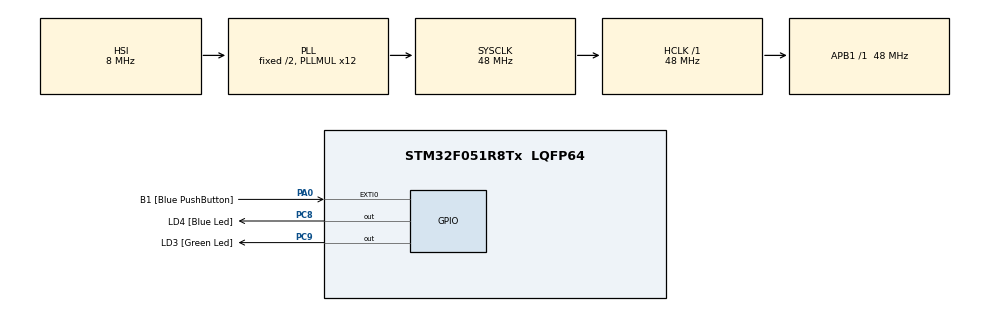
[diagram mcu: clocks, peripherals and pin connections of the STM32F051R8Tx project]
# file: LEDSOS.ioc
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Mcu.Family=STM32F0
Mcu.Name=STM32F051R8Tx
Mcu.Package=LQFP64
PA0.GPIO_Label=B1 [Blue PushButton]
PA0.GPIO_ModeDefaultEXTI=GPIO_MODE_EVT_RISING
PA0.Signal=GPXTI0
PA13.GPIO_Label=SWDIO
PA13.Signal=SYS_SWDIO
PA14.GPIO_Label=SWCLK
PA14.Signal=SYS_SWCLK
PC8.GPIO_Label=LD4 [Blue Led]
PC8.GPIO_PuPd=GPIO_PULLUP
PC8.Signal=GPIO_Output
PC9.GPIO_Label=LD3 [Green Led]
PC9.GPIO_PuPd=GPIO_PULLUP
PC9.Signal=GPIO_Output
ProjectManager.HeapSize=0x200
ProjectManager.StackSize=0x400
ProjectManager.TargetToolchain=TrueSTUDIO
RCC.AHBFreq_Value=48000000
RCC.APB1Freq_Value=48000000
RCC.APB1TimFreq_Value=48000000
RCC.HCLKFreq_Value=48000000
RCC.PLLMUL=RCC_PLL_MUL12
RCC.SYSCLKFreq_VALUE=48000000
RCC.SYSCLKSource=RCC_SYSCLKSOURCE_PLLCLK
board=STM32F0DISCOVERY

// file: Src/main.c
/**
  ******************************************************************************
  * File Name          : main.c
  * Description        : Main program body
  ******************************************************************************
  *
  * COPYRIGHT(c) 2016 STMicroelectronics
  *
  * Redistribution and use in source and binary forms, with or without modification,
  * are permitted provided that the following conditions are met:
  *   1. Redistributions of source code must retain the above copyright notice,
  *      this list of conditions and the following disclaimer.
  *   2. Redistributions in binary form must reproduce the above copyright notice,
  *      this list of conditions and the following disclaimer in the documentation
  *      and/or other materials provided with the distribution.
  *   3. Neither the name of STMicroelectronics nor the names of its contributors
  *      may be used to endorse or promote products derived from this software
  *      without specific prior written permission.
  *
  * THIS SOFTWARE IS PROVIDED BY THE COPYRIGHT HOLDERS AND CONTRIBUTORS "AS IS"
  * AND ANY EXPRESS OR IMPLIED WARRANTIES, INCLUDING, BUT NOT LIMITED TO, THE
  * IMPLIED WARRANTIES OF MERCHANTABILITY AND FITNESS FOR A PARTICULAR PURPOSE ARE
  * DISCLAIMED. IN NO EVENT SHALL THE COPYRIGHT HOLDER OR CONTRIBUTORS BE LIABLE
  * FOR ANY DIRECT, INDIRECT, INCIDENTAL, SPECIAL, EXEMPLARY, OR CONSEQUENTIAL
  * DAMAGES (INCLUDING, BUT NOT LIMITED TO, PROCUREMENT OF SUBSTITUTE GOODS OR
  * SERVICES; LOSS OF USE, DATA, OR PROFITS; OR BUSINESS INTERRUPTION) HOWEVER
  * CAUSED AND ON ANY THEORY OF LIABILITY, WHETHER IN CONTRACT, STRICT LIABILITY,
  * OR TORT (INCLUDING NEGLIGENCE OR OTHERWISE) ARISING IN ANY WAY OUT OF THE USE
  * OF THIS SOFTWARE, EVEN IF ADVISED OF THE POSSIBILITY OF SUCH DAMAGE.
  *
  ******************************************************************************
  */
#include "stm32f0xx_hal.h"

/* USER CODE BEGIN Includes */
#define UNIT 500

/* USER CODE END Includes */

/* USER CODE BEGIN PV */
/* Private variables ---------------------------------------------------------*/

/* USER CODE END PV */

void SystemClock_Config(void);
void Error_Handler(void);
static void MX_GPIO_Init(void);

/* USER CODE BEGIN PFP */
/* Private function prototypes -----------------------------------------------*/

/* USER CODE END PFP */

  void light_On()
  {
	  HAL_GPIO_WritePin(GPIOC, GPIO_PIN_8, GPIO_PIN_SET);
  }

  void light_Off()
  {
	  HAL_GPIO_WritePin(GPIOC, GPIO_PIN_8, GPIO_PIN_RESET);
  }

  void lightOnButtonPressed()
  {
	  uint8_t buttonState;

	  buttonState = HAL_GPIO_ReadPin(GPIOA, GPIO_PIN_0);

	  if (buttonState == 1)
	  	  {
	  		  HAL_GPIO_WritePin(GPIOC, GPIO_PIN_9, GPIO_PIN_SET);
	  	  }
	  else
	  	  {
	  		  HAL_GPIO_WritePin(GPIOC, GPIO_PIN_9, GPIO_PIN_RESET);
	  	  }
  }

  void getStrSize(uint8_t * str)
  {
	  for (int i = 0; i < sizeof(str) - 1; i++)
	  {
		  light_On();
		  HAL_Delay(UNIT);
		  light_Off();
		  HAL_Delay(UNIT);
	  }

	  HAL_Delay(10*UNIT);
  }

  void char_to_morse(uint8_t  symbol)
  {
	  switch (symbol)
	  	  {
	  	      case 'S': light_On(); HAL_Delay(2*UNIT); light_Off(); HAL_Delay(UNIT); return;
	  	      case 'O': light_On(); HAL_Delay(4*UNIT); light_Off(); HAL_Delay(UNIT); return;
	  	      case ' ': light_On(); HAL_Delay(UNIT);  light_Off();  HAL_Delay(UNIT); return;
	  	      default: return;
	  	  }
  }

  void str_to_morse(uint8_t * str)
  {
	  uint8_t symbol;

	  for(int i = 0; i < sizeof(str) - 1; i++)
	  {
	      symbol = str[i];
	      char_to_morse(symbol);
	  }

	  HAL_Delay(10*UNIT);
  }

int main(void)
{

  /* MCU Configuration----------------------------------------------------------*/

  /* Reset of all peripherals, Initializes the Flash interface and the Systick. */
  HAL_Init();

  /* Configure the system clock */
  SystemClock_Config();

  /* Initialize all configured peripherals */
  MX_GPIO_Init();

  /* Infinite loop */
  while (1)
  {

  /* USER CODE BEGIN 3 */

	  //lightOnButtonPressed();

	  //getStrSize("SOS");

	  str_to_morse("SOS");

  }
  /* USER CODE END 3 */

}

/** System Clock Configuration
*/
void SystemClock_Config(void)
{

  RCC_OscInitTypeDef RCC_OscInitStruct;
  RCC_ClkInitTypeDef RCC_ClkInitStruct;

  RCC_OscInitStruct.OscillatorType = RCC_OSCILLATORTYPE_HSI;
  RCC_OscInitStruct.HSIState = RCC_HSI_ON;
  RCC_OscInitStruct.HSICalibrationValue = 16;
  RCC_OscInitStruct.PLL.PLLState = RCC_PLL_ON;
  RCC_OscInitStruct.PLL.PLLSource = RCC_PLLSOURCE_HSI;
  RCC_OscInitStruct.PLL.PLLMUL = RCC_PLL_MUL12;
  RCC_OscInitStruct.PLL.PREDIV = RCC_PREDIV_DIV1;
  if (HAL_RCC_OscConfig(&RCC_OscInitStruct) != HAL_OK)
  {
    Error_Handler();
  }

  RCC_ClkInitStruct.ClockType = RCC_CLOCKTYPE_HCLK|RCC_CLOCKTYPE_SYSCLK
                              |RCC_CLOCKTYPE_PCLK1;
  RCC_ClkInitStruct.SYSCLKSource = RCC_SYSCLKSOURCE_PLLCLK;
  RCC_ClkInitStruct.AHBCLKDivider = RCC_SYSCLK_DIV1;
  RCC_ClkInitStruct.APB1CLKDivider = RCC_HCLK_DIV1;
  if (HAL_RCC_ClockConfig(&RCC_ClkInitStruct, FLASH_LATENCY_1) != HAL_OK)
  {
    Error_Handler();
  }

  HAL_SYSTICK_Config(HAL_RCC_GetHCLKFreq()/1000);

  HAL_SYSTICK_CLKSourceConfig(SYSTICK_CLKSOURCE_HCLK);

  /* SysTick_IRQn interrupt configuration */
  HAL_NVIC_SetPriority(SysTick_IRQn, 0, 0);
}

/** Configure pins as
        * Analog
        * Input
        * Output
        * EVENT_OUT
        * EXTI
*/
static void MX_GPIO_Init(void)
{

  GPIO_InitTypeDef GPIO_InitStruct;

  /* GPIO Ports Clock Enable */
  __HAL_RCC_GPIOA_CLK_ENABLE();
  __HAL_RCC_GPIOC_CLK_ENABLE();

  /*Configure GPIO pin : B1_Pin */
  GPIO_InitStruct.Pin = B1_Pin;
  GPIO_InitStruct.Mode = GPIO_MODE_EVT_RISING;
  GPIO_InitStruct.Pull = GPIO_NOPULL;
  HAL_GPIO_Init(B1_GPIO_Port, &GPIO_InitStruct);

  /*Configure GPIO pins : LD4_Pin LD3_Pin */
  GPIO_InitStruct.Pin = LD4_Pin|LD3_Pin;
  GPIO_InitStruct.Mode = GPIO_MODE_OUTPUT_PP;
  GPIO_InitStruct.Pull = GPIO_PULLUP;
  GPIO_InitStruct.Speed = GPIO_SPEED_FREQ_LOW;
  HAL_GPIO_Init(GPIOC, &GPIO_InitStruct);

  /*Configure GPIO pin Output Level */
  HAL_GPIO_WritePin(GPIOC, LD4_Pin|LD3_Pin, GPIO_PIN_RESET);

}

void Error_Handler(void)
{
  while(1)
  {
  }
}

/************************ (C) COPYRIGHT STMicroelectronics *****END OF FILE****/
